VERSION ""

NS_ :

BS_:

BU_: TEL VCU

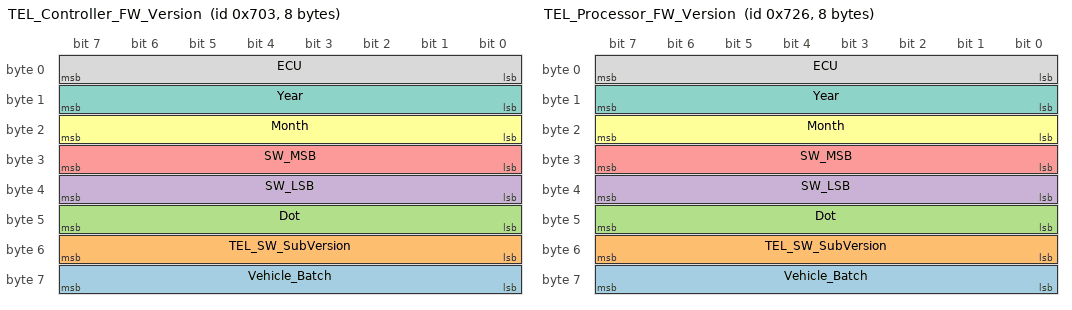
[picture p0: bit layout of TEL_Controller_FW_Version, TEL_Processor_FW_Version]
BO_ 1795 TEL_Controller_FW_Version: 8 TEL
 SG_ Vehicle_Batch : 56|8@1+ (1,0) [0|0] "" Vector__XXX
 SG_ TEL_SW_SubVersion : 48|8@1+ (1,0) [0|0] "" Vector__XXX
 SG_ Dot : 40|8@1+ (1,0) [0|0] "" Vector__XXX
 SG_ SW_LSB : 32|8@1+ (1,0) [0|0] "" Vector__XXX
 SG_ SW_MSB : 24|8@1+ (1,0) [0|0] "" Vector__XXX
 SG_ Month : 16|8@1+ (1,0) [0|0] "" Vector__XXX
 SG_ Year : 8|8@1+ (1,0) [0|0] "" Vector__XXX
 SG_ ECU : 0|8@1+ (1,0) [0|0] "" Vector__XXX

BO_ 1830 TEL_Processor_FW_Version: 8 TEL
 SG_ Vehicle_Batch : 56|8@1+ (1,0) [0|0] "" Vector__XXX
 SG_ TEL_SW_SubVersion : 48|8@1+ (1,0) [0|0] "" Vector__XXX
 SG_ Dot : 40|8@1+ (1,0) [0|0] "" Vector__XXX
 SG_ SW_LSB : 32|8@1+ (1,0) [0|0] "" Vector__XXX
 SG_ SW_MSB : 24|8@1+ (1,0) [0|0] "" Vector__XXX
 SG_ Month : 16|8@1+ (1,0) [0|0] "" Vector__XXX
 SG_ Year : 8|8@1+ (1,0) [0|0] "" Vector__XXX
 SG_ ECU : 0|8@1+ (1,0) [0|0] "" Vector__XXX

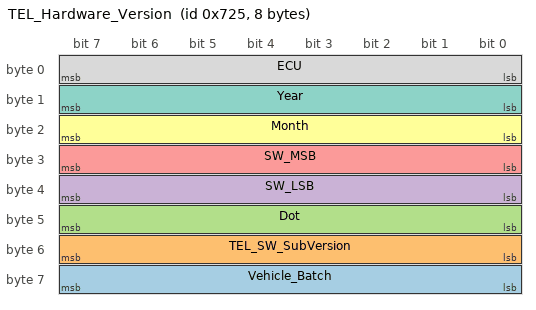
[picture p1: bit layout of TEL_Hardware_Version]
BO_ 1829 TEL_Hardware_Version: 8 TEL
 SG_ Vehicle_Batch : 56|8@1+ (1,0) [0|0] "" Vector__XXX
 SG_ TEL_SW_SubVersion : 48|8@1+ (1,0) [0|0] "" Vector__XXX
 SG_ Dot : 40|8@1+ (1,0) [0|0] "" Vector__XXX
 SG_ SW_LSB : 32|8@1+ (1,0) [0|0] "" Vector__XXX
 SG_ SW_MSB : 24|8@1+ (1,0) [0|0] "" Vector__XXX
 SG_ Month : 16|8@1+ (1,0) [0|0] "" Vector__XXX
 SG_ Year : 8|8@1+ (1,0) [0|0] "" Vector__XXX
 SG_ ECU : 0|8@1+ (1,0) [0|0] "" Vector__XXX

BO_ 819 TEL_Lat_Long_Signal: 8 TEL
 SG_ TEL_Lat_Long_Signal_Raw : 0|64@1+ (1,0) [0|0] "" Vector__XXX

CM_ BO_ 1795 "Controller firmware version info";
CM_ SG_ 1795 Dot "ASCII '.'";
CM_ SG_ 1795 Year "24 = 2024";
CM_ SG_ 1795 ECU "ASCII 'T' = telematics";
CM_ BO_ 1830 "Processor firmware version info";
CM_ SG_ 1830 Dot "ASCII '.'";
CM_ SG_ 1830 Year "24 = 2024";
CM_ SG_ 1830 ECU "ASCII 'T' = telematics";
CM_ BO_ 1829 "Hardware version info";
CM_ SG_ 1829 Dot "ASCII '.'";
CM_ SG_ 1829 Year "24 = 2024";
CM_ SG_ 1829 ECU "ASCII 'T' = telematics";
CM_ BO_ 819 "Lat, Long and signal strength - byte layout is defined in River DBC v4.20, not in the PRD; kept as a raw 64-bit value.";
BA_DEF_ BO_  "GenMsgCycleTime" INT 0 65535;
BA_DEF_DEF_  "GenMsgCycleTime" 0;
BA_ "GenMsgCycleTime" BO_ 1795 10000;
BA_ "GenMsgCycleTime" BO_ 1830 10000;
BA_ "GenMsgCycleTime" BO_ 1829 10000;
BA_ "GenMsgCycleTime" BO_ 819 1000;
VAL_ 1795 Vehicle_Batch 84 "T (test)" 80 "P (production)" ;
VAL_ 1830 Vehicle_Batch 84 "T (test)" 80 "P (production)" ;
VAL_ 1829 Vehicle_Batch 84 "T (test)" 80 "P (production)" ;
